# GENERAL_WKUP register map
Vendor: Texas Instruments
Peripheral module from a debugger description file (folder omap36xx).
Registers are 32-bit, access per field, reset 0x0 unless marked. A register's access mark holds for its fields unless they carry their own. Offsets are as the file gives them; lines under a group give offsets from that group; [hi:lo] are bit positions; {n}, {i} and the like mark numbered series; 'fields as' and 'values as' point back to an identical list; <NAME> marks a mode.

## GENERAL_WKUP
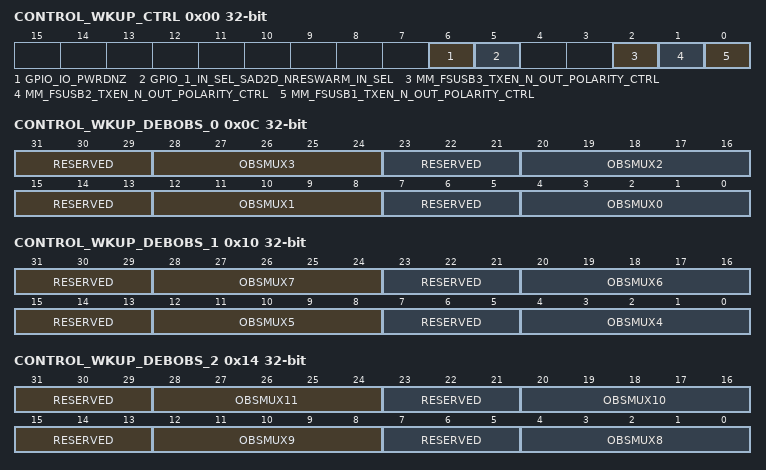
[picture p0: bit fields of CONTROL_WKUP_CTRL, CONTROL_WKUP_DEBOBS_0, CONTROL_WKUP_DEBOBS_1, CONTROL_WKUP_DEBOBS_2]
0x00 CONTROL_WKUP_CTRL — register description
  [6] GPIO_IO_PWRDNZ rw — Software must keep this signal 0 whenever SIM_VDDS voltage is changing.When GPIO_IO_PWRDNZ is 0, input and output buffers in the gpio126, gpio127, and gpio129 associated exteneded-drain I/O cell are disabled. Pad can be pulled down by asserting the PIPD pin.
  [5] GPIO_1_IN_SEL_SAD2D_NRESWARM_IN_SEL rw — Mux select for GPIO1/SAD2D_NRESWARM bit
  [2] MM_FSUSB3_TXEN_N_OUT_POLARITY_CTRL rw — Polarity control for TXEN signal of multimode USB interface port30 : Active low1 : Active high
  [1] MM_FSUSB2_TXEN_N_OUT_POLARITY_CTRL rw — Polarity control for TXEN signal of multimode USB interface port20 : Active low1 : Active high
  [0] MM_FSUSB1_TXEN_N_OUT_POLARITY_CTRL rw — Polarity control for TXEN signal of multimode USB interface port10 : Active low1 : Active high
0x0C CONTROL_WKUP_DEBOBS_0 access not given — Select the WKUP domain set of signals to be observed for hw_dbg3, hw_dbg2, hw_dbg1, hw_dbg0
  [31:29] RESERVED ro — Read returns reset value.
  [8n+4:8n] OBSMUX{n} (n=0..3) — Select the set of signals to be observed for hw_dbg{n} (access See)
  [23:21] RESERVED ro — Read returns reset value.
  [15:13] RESERVED ro — Read returns reset value.
  [7:5] RESERVED ro — Read returns reset value.
0x10 CONTROL_WKUP_DEBOBS_1 access not given — Select the WKUP domain set of signals to be observed for hw_dbg7, hw_dbg6, hw_dbg5, hw_dbg4
  [31:29] RESERVED ro — Read returns reset value.
  [8n-28:8n-32] OBSMUX{n} (n=4..7) — Select the set of signals to be observed for hw_dbg{n} (access See)
  [23:21] RESERVED ro — Read returns reset value.
  [15:13] RESERVED ro — Read returns reset value.
  [7:5] RESERVED ro — Read returns reset value.
0x14 CONTROL_WKUP_DEBOBS_2 access not given — Select the WKUP domain set of signals to be observed for hw_dbg11 hw_dbg10, hw_dbg9, hw_dbg8
  [31:29] RESERVED ro — Read returns reset value.
  [8n-60:8n-64] OBSMUX{n} (n=8..11) — Select the set of signals to be observed for hw_dbg{n} (access See)
  [23:21] RESERVED ro — Read returns reset value.
  [15:13] RESERVED ro — Read returns reset value.
  [7:5] RESERVED ro — Read returns reset value.
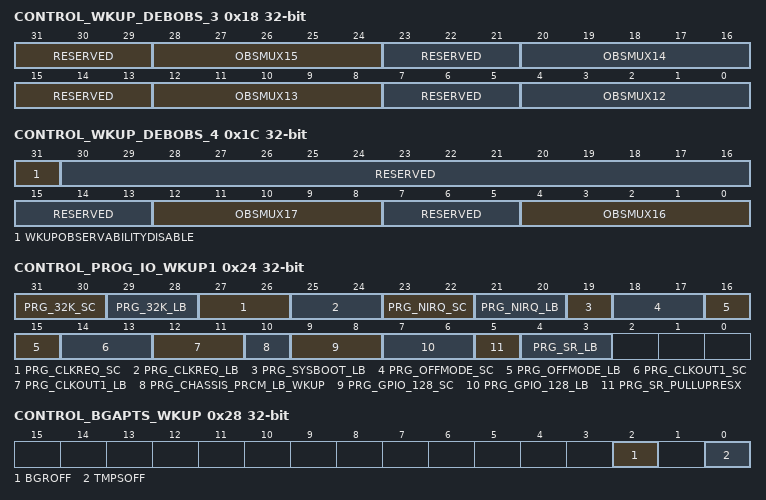
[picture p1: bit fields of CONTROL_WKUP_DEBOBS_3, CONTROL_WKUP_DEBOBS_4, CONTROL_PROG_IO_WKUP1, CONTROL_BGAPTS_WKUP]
0x18 CONTROL_WKUP_DEBOBS_3 access not given — Select the WKUP domain set of signals to be observed for hw_dbg15 hw_dbg14, hw_dbg13, hw_dbg12
  [31:29] RESERVED ro — Read returns reset value.
  [8n-92:8n-96] OBSMUX{n} (n=12..15) — Select the set of signals to be observed for hw_dbg{n} (access See)
  [23:21] RESERVED ro — Read returns reset value.
  [15:13] RESERVED ro — Read returns reset value.
  [7:5] RESERVED ro — Read returns reset value.
0x1C CONTROL_WKUP_DEBOBS_4 access not given — Select the WKUP domain set of signals to be observed for hw_dbg17, hw_dbg16
  [31] WKUPOBSERVABILITYDISABLE — Control the observability feature (access See)
  [30:13] RESERVED ro — Read returns reset value.
  [12:8] OBSMUX17 — Select the set of signals to be observed for hw_dbg17 (access See)
  [7:5] RESERVED ro — Read returns reset value.
  [4:0] OBSMUX16 — Select the set of signals to be observed for hw_dbg16 (access See)
0x24 CONTROL_PROG_IO_WKUP1 — register description
  [31:30] PRG_32K_SC rw — Slew rate control bits.Format used in the field name below is : (programmable_group_name)_(configurable_pin on I/O cell) See for the allowed SC vs LB bitfield combinations.
  [29:28] PRG_32K_LB rw — Effective TL length and farend capacitive load controls. This bit allows control of programmable drive/slew control on I/O cell. Format used in the field name below is: (programmable_group_name)_(configurable_pin on IO cell)See for the allowed SC vs LB bitfield combinations.
  [27:26] PRG_CLKREQ_SC rw — Slew rate control bits.Format used in the field name below is: (programmable_group_name)_(configurable_pin on I/O cell) See for the allowed SC vs LB bitfield combinations.
  [25:24] PRG_CLKREQ_LB rw — Effective TL length and farend capacitive load controls. This bit allows control of programmable drive/slew control on I/O cell. Format used in the field name below is: (programmable_group_name)_(configurable_pin on I/O cell)See for the allowed SC vs LB bitfield combinations.
  [23:22] PRG_NIRQ_SC rw — Slew rate control bits.Format used in the field name below is: (programmable_group_name)_(configurable_pin on I/O cell) See for the allowed SC vs LB bitfield combinations.
  [21:20] PRG_NIRQ_LB rw — Effective TL length and farend capacitive load controls. This bit allows control of programmable drive/slew control on IO cell. Format used in the field name below is: (programmable_group_name)_(configurable_pin on I/O cell)See for the allowed SC vs LB bitfield combinations.
  [19] PRG_SYSBOOT_LB rw — Format used in the field name below is: (programmable_group_name)_(configurable_pin on I/O cell)Far end load setting.Transmission Line (TL) characteristic impedance is 50 Ohm, TL capacitance =1pF / cm: 0x0: Far end load = [1pF-10pF] / TL length=[1cm-6cm] 0x1: Far end load = [10pF-16pF] / TL length=[1cm-6cm]
  [18:17] PRG_OFFMODE_SC rw — Slew rate control bits.Format used in the field name below is: (programmable_group_name)_(configurable_pin on I/O cell) See for the allowed SC vs LB bitfield combinations.
  [16:15] PRG_OFFMODE_LB rw — Effective TL length and farend capacitive load controls. This bit allows control of programmable drive/slew control on I/O cell. Format used in the field name below is: (programmable_group_name)_(configurable_pin on I/O cell)See for the allowed SC vs LB bitfield combinations.
  [14:13] PRG_CLKOUT1_SC rw — Slew rate control bits.Format used in the field name below is: (programmable_group_name)_(configurable_pin on I/O cell) See for the allowed SC vs LB bitfield combinations.
  [12:11] PRG_CLKOUT1_LB rw — Effective TL length and farend capacitive load controls. This bit allows control of programmable drive/slew control on IO cell. Format used in the field name below is: (programmable_group_name)_(configurable_pin on I/O cell)See for the allowed SC vs LB bitfield combinations.
  [10] PRG_CHASSIS_PRCM_LB_WKUP rw — Format used in the field name below is: (programmable_group_name)_(configurable_pin on I/O cell)Far-end load setting.Transmission Line (TL) characteristic impedance is 50 Ohm, TL capacitance =1pF / cm: 0x0: Far-end load = [1pF-10pF] / TL length=[1cm-6cm] 0x1: Far-end load = [10pF-16pF] / TL length=[1cm-6cm]
  [9:8] PRG_GPIO_128_SC rw — Slew rate control bits. Format used in the field name below is: (programmable_group_name)_(configurable_pin on I/O cell) See for the allowed SC vs LB bit field combinations.
  [7:6] PRG_GPIO_128_LB rw — Effective TL length and farend capacitive load controls. This bit allows control of programmable drive/slew control on I/O cell.Format used in the field name below is: (programmable_group_name)_(configurable_pin on IO cell) See for the allowed SC vs LB bit field combinations.
  [5] PRG_SR_PULLUPRESX rw — Format used in the field name below is: (programmable_group_name)_(configurable_pin on IO cell)(SR interface) I2C4 pad group control for external / internal pull-up resistor enable:0x0: Enables internal pull-ups for the I2C4 pad group0x1: Disables internal pull-ups for the I2C4 pad group
  [4:3] PRG_SR_LB rw — The bits select a proper resistor value for the (SR interface) I2C4 pull-ups for a given load range at FS / HS modes.Format used in the field name below is : (programmable_group_name)_(configurable_pin on IO cell)FS mode :0b00: 4,5K Ohms / 5-15pF cap.load0b01: 2,1K Ohms /15-50pF cap.load0b10: 860 Ohms / 50-150pF cap.load0b11: ReservedHS mode :0b00: 1,66K Ohms / 5-12pF cap.load0b01: 920 Ohms / 12-25pF cap.load0b10: 500 Ohms/ 25-50pF cap.load0b11: 300 Ohms/ 50-80pF cap.loadSee for example [LB1:LB0] bitfield vs PRG_I2C4_PULLUPRESX bit combinations.
0x28 CONTROL_BGAPTS_WKUP — register description
  [2] BGROFF rw — Used for ON/OFF control of BGAPTS module0 : BGAP is ON1 : BGAP is OFFNote : BGAP cannot be turned off with TMPS ON. i.e. BGROFF 1 AND TMPSOFF 0 is not allowed
  [0] TMPSOFF rw — Used to control the TMPSOFF input of BGAPTS module1 : Temperature sensor and thermal shutdown in OFF mode0 : Temperature sensor and thermal shutdown ON
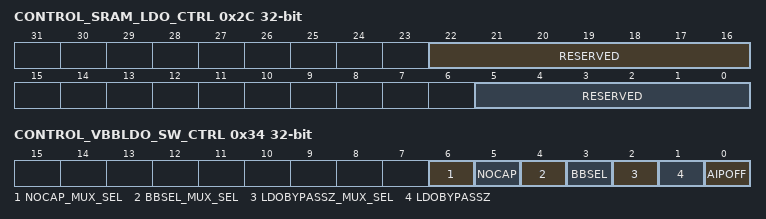
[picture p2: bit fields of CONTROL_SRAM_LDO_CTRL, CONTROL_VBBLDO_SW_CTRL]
0x2C CONTROL_SRAM_LDO_CTRL — register description
  [22:16] RESERVED rw — Write the reset value; read returns the reset value.
  [5:0] RESERVED rw — Write the reset value; read returns the reset value.
0x34 CONTROL_VBBLDO_SW_CTRL — register description
  [6] NOCAP_MUX_SEL rw — Enable NOCAP Override
  [5] NOCAP rw — Override NOCAP
  [4] BBSEL_MUX_SEL rw — Enables BBSEL Override
  [3] BBSEL rw — Override for BBSEL signal
  [2] LDOBYPASSZ_MUX_SEL rw — Enable LDOBYPASSZ Override
  [1] LDOBYPASSZ rw — Override LDOBYPASSZ
  [0] AIPOFF rw — Override AIPOFF input. When high will act as AIPOFF for VBBLDO
